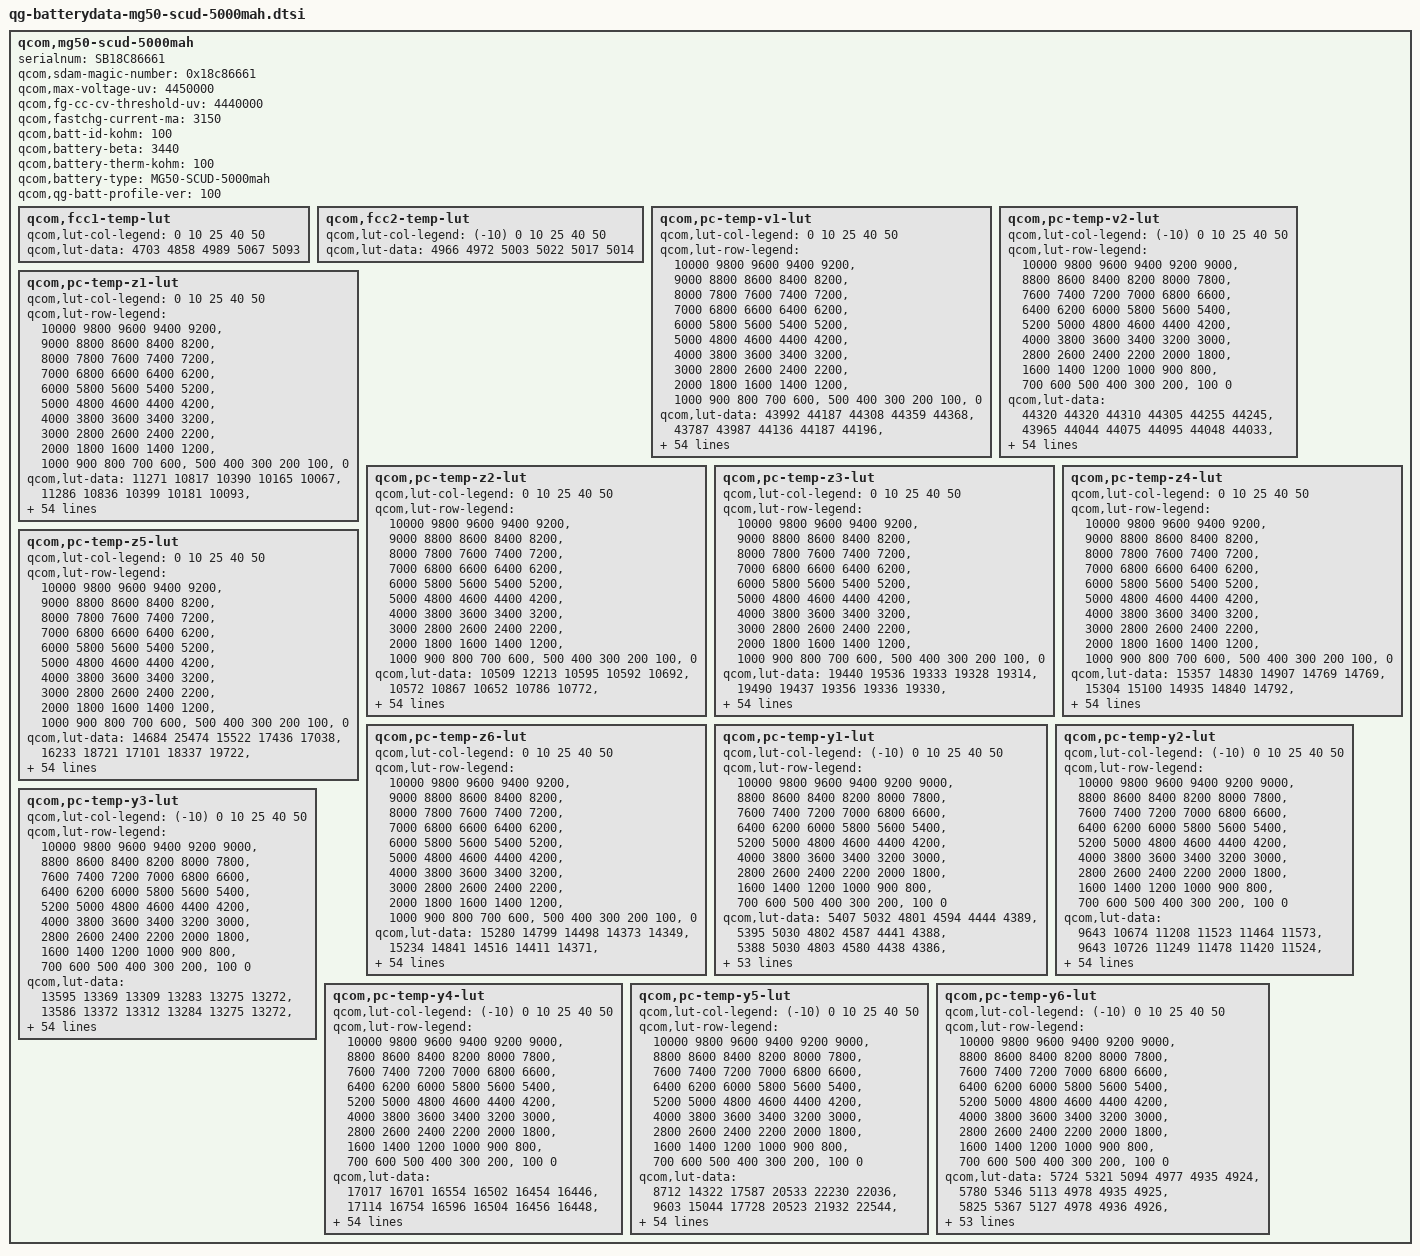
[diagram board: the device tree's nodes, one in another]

qcom,mg50-scud-5000mah {
    /* 4694403_Lenovo_ MG50_5000mAH_PM7150_averaged_MasterSlave_Jul8th2020 */
    serialnum = "SB18C86661";
    qcom,sdam-magic-number = <0x18c86661>;
    qcom,max-voltage-uv = <4450000>;
    qcom,fg-cc-cv-threshold-uv = <4440000>;
    qcom,fastchg-current-ma = <3150>;
    qcom,batt-id-kohm = <100>;
    qcom,battery-beta = <3440>;
    qcom,battery-therm-kohm = <100>;
    qcom,battery-type = "MG50-SCUD-5000mah";
    qcom,qg-batt-profile-ver = <100>;

	qcom,fcc1-temp-lut {
		qcom,lut-col-legend = <0 10 25 40 50>;
		qcom,lut-data = <4703 4858 4989 5067 5093>;
	};

	qcom,fcc2-temp-lut {
		qcom,lut-col-legend = <(-10) 0 10 25 40 50>;
		qcom,lut-data = <4966 4972 5003 5022 5017 5014>;
	};

	qcom,pc-temp-v1-lut {
		qcom,lut-col-legend = <0 10 25 40 50>;
		qcom,lut-row-legend = <10000 9800 9600 9400 9200>,
			<9000 8800 8600 8400 8200>,
			<8000 7800 7600 7400 7200>,
			<7000 6800 6600 6400 6200>,
			<6000 5800 5600 5400 5200>,
			<5000 4800 4600 4400 4200>,
			<4000 3800 3600 3400 3200>,
			<3000 2800 2600 2400 2200>,
			<2000 1800 1600 1400 1200>,
			<1000 900 800 700 600>,
			<500 400 300 200 100>,
			<0>;
		qcom,lut-data = <43992 44187 44308 44359 44368>,
			<43787 43987 44136 44187 44196>,
			<43576 43790 43955 44013 44021>,
			<43356 43593 43768 43830 43841>,
			<43130 43382 43574 43639 43649>,
			<42900 43153 43366 43436 43446>,
			<42669 42917 43138 43219 43231>,
			<42437 42681 42897 42986 43003>,
			<42210 42445 42656 42748 42767>,
			<41984 42212 42414 42508 42527>,
			<41763 41981 42176 42267 42284>,
			<41548 41754 41943 42027 42043>,
			<41338 41531 41714 41789 41805>,
			<41135 41313 41487 41554 41570>,
			<40938 41101 41264 41326 41342>,
			<40745 40900 41047 41103 41118>,
			<40544 40703 40841 40888 40901>,
			<40336 40507 40641 40680 40691>,
			<40137 40318 40447 40479 40489>,
			<39960 40111 40260 40289 40296>,
			<39792 39838 40051 40097 40106>,
			<39601 39527 39772 39858 39879>,
			<39348 39311 39483 39569 39596>,
			<39106 39182 39288 39332 39349>,
			<38966 39077 39151 39169 39179>,
			<38877 38974 39027 39033 39041>,
			<38804 38875 38904 38905 38911>,
			<38736 38780 38788 38786 38789>,
			<38674 38688 38681 38676 38677>,
			<38613 38601 38583 38575 38575>,
			<38555 38525 38493 38482 38480>,
			<38499 38456 38411 38396 38389>,
			<38448 38394 38336 38317 38303>,
			<38400 38339 38269 38241 38219>,
			<38353 38289 38211 38167 38140>,
			<38308 38239 38154 38093 38059>,
			<38262 38190 38096 38019 37967>,
			<38200 38131 38036 37942 37864>,
			<38105 38044 37954 37852 37757>,
			<37989 37928 37843 37739 37647>,
			<37860 37799 37718 37611 37526>,
			<37710 37652 37581 37466 37379>,
			<37548 37495 37433 37313 37218>,
			<37386 37322 37270 37162 37076>,
			<37296 37203 37151 37062 36985>,
			<37234 37143 37085 37008 36940>,
			<37213 37119 37064 36991 36919>,
			<37177 37097 37042 36968 36891>,
			<37093 37013 36995 36881 36770>,
			<36837 36728 36765 36589 36457>,
			<36416 36308 36380 36181 36041>,
			<35905 35782 35892 35672 35518>,
			<35256 35108 35271 35016 34844>,
			<34366 34175 34438 34118 33914>,
			<32964 32671 33161 32689 32396>,
			<30000 30000 30000 30000 30000>;
	};

	qcom,pc-temp-v2-lut {
		qcom,lut-col-legend = <(-10) 0 10 25 40 50>;
		qcom,lut-row-legend = <10000 9800 9600 9400 9200 9000>,
			<8800 8600 8400 8200 8000 7800>,
			<7600 7400 7200 7000 6800 6600>,
			<6400 6200 6000 5800 5600 5400>,
			<5200 5000 4800 4600 4400 4200>,
			<4000 3800 3600 3400 3200 3000>,
			<2800 2600 2400 2200 2000 1800>,
			<1600 1400 1200 1000 900 800>,
			<700 600 500 400 300 200>,
			<100 0>;
		qcom,lut-data = <44320 44320 44310 44305 44255 44245>,
			<43965 44044 44075 44095 44048 44033>,
			<43646 43783 43847 43888 43841 43823>,
			<43373 43539 43629 43685 43637 43617>,
			<43143 43315 43421 43488 43435 43416>,
			<42908 43087 43207 43282 43225 43208>,
			<42630 42844 42973 43057 42999 42983>,
			<42340 42594 42730 42821 42764 42748>,
			<42086 42343 42487 42584 42527 42512>,
			<41863 42089 42241 42342 42285 42270>,
			<41647 41842 41999 42102 42045 42029>,
			<41428 41608 41761 41864 41808 41793>,
			<41213 41383 41529 41629 41574 41560>,
			<41004 41167 41299 41397 41343 41330>,
			<40805 40963 41074 41169 41116 41105>,
			<40578 40755 40857 40947 40896 40885>,
			<40259 40529 40659 40736 40686 40673>,
			<39887 40290 40462 40529 40481 40466>,
			<39600 40041 40233 40320 40280 40266>,
			<39384 39773 39964 40108 40081 40074>,
			<39175 39515 39701 39882 39866 39865>,
			<38919 39278 39458 39614 39598 39600>,
			<38655 39058 39235 39349 39329 39331>,
			<38476 38866 39047 39147 39129 39131>,
			<38357 38700 38886 38984 38972 38974>,
			<38268 38544 38739 38838 38832 38835>,
			<38200 38376 38602 38707 38702 38704>,
			<38145 38214 38476 38587 38583 38585>,
			<38091 38108 38361 38475 38473 38473>,
			<38039 38040 38255 38370 38369 38369>,
			<37988 37985 38157 38273 38275 38273>,
			<37936 37937 38060 38184 38191 38188>,
			<37883 37894 37970 38101 38111 38107>,
			<37825 37849 37897 38020 38020 38010>,
			<37765 37801 37839 37941 37922 37899>,
			<37700 37750 37782 37854 37818 37781>,
			<37631 37693 37725 37753 37704 37659>,
			<37555 37629 37664 37647 37588 37540>,
			<37471 37549 37587 37551 37483 37435>,
			<37374 37443 37489 37460 37385 37340>,
			<37268 37320 37378 37358 37278 37235>,
			<37155 37185 37245 37239 37152 37105>,
			<37039 37047 37105 37110 37022 36966>,
			<36935 36937 36976 36976 36901 36845>,
			<36842 36840 36886 36904 36847 36794>,
			<36755 36736 36814 36872 36826 36773>,
			<36697 36666 36774 36851 36804 36749>,
			<36625 36570 36701 36819 36747 36685>,
			<36516 36434 36561 36717 36519 36442>,
			<36310 36227 36288 36408 36124 36042>,
			<35943 35905 35849 35958 35619 35539>,
			<35435 35440 35261 35395 34979 34899>,
			<34753 34787 34498 34661 34122 34049>,
			<33802 33857 33411 33658 32882 32885>,
			<32232 32353 31745 32182 31983 31219>,
			<29119 29764 27700 30619 28847 27763>;
	};

	qcom,pc-temp-z1-lut {
		qcom,lut-col-legend = <0 10 25 40 50>;
		qcom,lut-row-legend = <10000 9800 9600 9400 9200>,
			<9000 8800 8600 8400 8200>,
			<8000 7800 7600 7400 7200>,
			<7000 6800 6600 6400 6200>,
			<6000 5800 5600 5400 5200>,
			<5000 4800 4600 4400 4200>,
			<4000 3800 3600 3400 3200>,
			<3000 2800 2600 2400 2200>,
			<2000 1800 1600 1400 1200>,
			<1000 900 800 700 600>,
			<500 400 300 200 100>,
			<0>;
		qcom,lut-data = <11271 10817 10390 10165 10067>,
			<11286 10836 10399 10181 10093>,
			<11296 10836 10405 10182 10097>,
			<11300 10829 10405 10181 10098>,
			<11299 10822 10395 10176 10098>,
			<11292 10819 10383 10169 10096>,
			<11279 10816 10368 10164 10094>,
			<11261 10801 10354 10160 10093>,
			<11237 10778 10347 10157 10092>,
			<11206 10765 10343 10154 10091>,
			<11187 10758 10340 10151 10090>,
			<11181 10753 10336 10149 10088>,
			<11176 10747 10333 10147 10087>,
			<11171 10741 10331 10146 10087>,
			<11161 10738 10330 10145 10087>,
			<11153 10737 10328 10144 10087>,
			<11151 10737 10326 10144 10087>,
			<11142 10737 10325 10143 10088>,
			<11134 10738 10325 10144 10088>,
			<11136 10739 10327 10144 10089>,
			<11142 10738 10327 10145 10090>,
			<11147 10738 10328 10146 10090>,
			<11145 10741 10328 10146 10091>,
			<11144 10748 10329 10147 10092>,
			<11146 10754 10331 10149 10094>,
			<11153 10756 10333 10152 10096>,
			<11159 10757 10337 10154 10098>,
			<11160 10757 10343 10157 10100>,
			<11158 10757 10346 10160 10102>,
			<11160 10758 10349 10164 10105>,
			<11172 10759 10353 10167 10107>,
			<11182 10760 10360 10170 10110>,
			<11181 10761 10368 10174 10113>,
			<11179 10762 10373 10178 10116>,
			<11178 10765 10377 10183 10120>,
			<11180 10769 10380 10187 10123>,
			<11183 10777 10384 10192 10126>,
			<11188 10786 10388 10195 10130>,
			<11200 10795 10393 10200 10133>,
			<11213 10805 10399 10205 10136>,
			<11221 10810 10405 10209 10139>,
			<11232 10809 10410 10213 10142>,
			<11239 10812 10417 10216 10144>,
			<11244 10828 10424 10218 10146>,
			<11262 10834 10432 10223 10148>,
			<11246 10832 10440 10227 10151>,
			<11236 10824 10440 10229 10153>,
			<11251 10838 10438 10231 10155>,
			<11270 10838 10445 10237 10158>,
			<11265 10850 10448 10240 10161>,
			<11282 10857 10455 10247 10167>,
			<11289 10871 10468 10252 10172>,
			<11290 10887 10487 10262 10181>,
			<11311 10903 10491 10275 10192>,
			<11311 10903 10491 10275 10192>,
			<11311 10903 10491 10275 10192>;
	};

	qcom,pc-temp-z2-lut {
		qcom,lut-col-legend = <0 10 25 40 50>;
		qcom,lut-row-legend = <10000 9800 9600 9400 9200>,
			<9000 8800 8600 8400 8200>,
			<8000 7800 7600 7400 7200>,
			<7000 6800 6600 6400 6200>,
			<6000 5800 5600 5400 5200>,
			<5000 4800 4600 4400 4200>,
			<4000 3800 3600 3400 3200>,
			<3000 2800 2600 2400 2200>,
			<2000 1800 1600 1400 1200>,
			<1000 900 800 700 600>,
			<500 400 300 200 100>,
			<0>;
		qcom,lut-data = <10509 12213 10595 10592 10692>,
			<10572 10867 10652 10786 10772>,
			<10596 10761 10823 10834 10920>,
			<10589 10757 11229 10840 10927>,
			<10565 10738 12090 10771 10875>,
			<10534 10690 12548 10673 10800>,
			<10494 10640 11850 10625 10750>,
			<10455 10591 10829 10597 10695>,
			<10428 10542 10590 10570 10635>,
			<10405 10522 10589 10528 10615>,
			<10389 10529 10622 10490 10609>,
			<10382 10544 10996 10484 10600>,
			<10377 10554 11370 10500 10572>,
			<10378 10561 11441 10514 10545>,
			<10390 10570 11479 10512 10547>,
			<10408 10582 11533 10508 10566>,
			<10421 10596 11872 10521 10593>,
			<10432 10609 12572 10557 10635>,
			<10441 10619 12909 10590 10674>,
			<10450 10634 13044 10609 10697>,
			<10459 10668 13073 10628 10719>,
			<10469 10712 12280 10682 10783>,
			<10485 10719 11069 10800 10972>,
			<10497 10658 10768 10928 11106>,
			<10499 10601 10760 11085 11091>,
			<10498 10605 10778 11196 11017>,
			<10497 10636 10834 11108 10917>,
			<10495 10663 10888 10829 10735>,
			<10492 10682 10862 10655 10601>,
			<10492 10694 10767 10587 10517>,
			<10497 10693 10696 10542 10464>,
			<10507 10683 10681 10513 10470>,
			<10514 10676 10685 10491 10518>,
			<10520 10681 10700 10491 10578>,
			<10526 10690 10722 10552 10648>,
			<10534 10700 10750 10640 10729>,
			<10543 10713 10792 10709 10829>,
			<10552 10728 10845 10779 10951>,
			<10561 10742 10901 10864 11008>,
			<10568 10758 10969 10991 11017>,
			<10567 10761 11003 11074 11022>,
			<10563 10744 10961 11069 11032>,
			<10565 10733 10913 11047 11034>,
			<10576 10738 10910 11004 11005>,
			<10421 10832 10883 10888 10900>,
			<10358 10830 10793 10764 10801>,
			<10255 10808 10772 10793 10842>,
			<10301 10812 10794 10878 10982>,
			<10399 10874 10866 10897 10969>,
			<10414 10909 10847 10684 10662>,
			<10102 10754 10705 10587 10591>,
			<10025 10700 10660 10537 10539>,
			<9921 10549 10590 10477 10489>,
			<9728 10435 10529 10406 10393>,
			<9728 10435 10529 10406 10393>,
			<9728 10435 10529 10406 10393>;
	};

	qcom,pc-temp-z3-lut {
		qcom,lut-col-legend = <0 10 25 40 50>;
		qcom,lut-row-legend = <10000 9800 9600 9400 9200>,
			<9000 8800 8600 8400 8200>,
			<8000 7800 7600 7400 7200>,
			<7000 6800 6600 6400 6200>,
			<6000 5800 5600 5400 5200>,
			<5000 4800 4600 4400 4200>,
			<4000 3800 3600 3400 3200>,
			<3000 2800 2600 2400 2200>,
			<2000 1800 1600 1400 1200>,
			<1000 900 800 700 600>,
			<500 400 300 200 100>,
			<0>;
		qcom,lut-data = <19440 19536 19333 19328 19314>,
			<19490 19437 19356 19336 19330>,
			<19522 19430 19374 19350 19343>,
			<19539 19445 19391 19360 19351>,
			<19550 19455 19409 19364 19357>,
			<19556 19463 19417 19368 19362>,
			<19559 19468 19413 19369 19363>,
			<19560 19469 19404 19369 19362>,
			<19560 19468 19397 19369 19360>,
			<19559 19465 19393 19366 19358>,
			<19557 19459 19392 19363 19356>,
			<19553 19453 19395 19361 19355>,
			<19548 19449 19397 19359 19353>,
			<19541 19446 19395 19358 19351>,
			<19533 19443 19391 19355 19348>,
			<19527 19440 19388 19353 19345>,
			<19525 19438 19388 19350 19342>,
			<19525 19435 19389 19348 19339>,
			<19524 19432 19388 19345 19336>,
			<19523 19430 19385 19341 19332>,
			<19522 19436 19381 19337 19329>,
			<19523 19449 19378 19337 19329>,
			<19531 19453 19374 19340 19332>,
			<19540 19441 19370 19345 19338>,
			<19540 19429 19364 19363 19354>,
			<19535 19429 19363 19383 19374>,
			<19530 19431 19376 19385 19377>,
			<19526 19435 19393 19382 19372>,
			<19524 19442 19397 19378 19367>,
			<19522 19448 19397 19372 19359>,
			<19522 19449 19394 19365 19352>,
			<19521 19448 19390 19359 19346>,
			<19521 19446 19385 19352 19341>,
			<19520 19444 19380 19346 19336>,
			<19519 19442 19375 19340 19329>,
			<19517 19439 19371 19337 19323>,
			<19514 19436 19368 19337 19324>,
			<19510 19433 19366 19337 19329>,
			<19506 19429 19366 19338 19332>,
			<19501 19426 19367 19342 19333>,
			<19498 19423 19368 19345 19334>,
			<19496 19421 19366 19345 19336>,
			<19491 19418 19363 19346 19337>,
			<19481 19415 19363 19348 19338>,
			<19357 19398 19354 19341 19335>,
			<19306 19386 19341 19324 19315>,
			<19263 19385 19338 19318 19311>,
			<19262 19377 19336 19313 19305>,
			<19262 19374 19328 19315 19309>,
			<19262 19372 19340 19332 19322>,
			<19264 19363 19348 19334 19323>,
			<19264 19361 19350 19335 19323>,
			<19265 19353 19351 19336 19324>,
			<19269 19347 19351 19335 19326>,
			<19269 19347 19351 19335 19326>,
			<19269 19347 19351 19335 19326>;
	};

	qcom,pc-temp-z4-lut {
		qcom,lut-col-legend = <0 10 25 40 50>;
		qcom,lut-row-legend = <10000 9800 9600 9400 9200>,
			<9000 8800 8600 8400 8200>,
			<8000 7800 7600 7400 7200>,
			<7000 6800 6600 6400 6200>,
			<6000 5800 5600 5400 5200>,
			<5000 4800 4600 4400 4200>,
			<4000 3800 3600 3400 3200>,
			<3000 2800 2600 2400 2200>,
			<2000 1800 1600 1400 1200>,
			<1000 900 800 700 600>,
			<500 400 300 200 100>,
			<0>;
		qcom,lut-data = <15357 14830 14907 14769 14769>,
			<15304 15100 14935 14840 14792>,
			<15240 15093 14900 14817 14789>,
			<15158 15006 14850 14784 14760>,
			<15063 14931 14782 14758 14737>,
			<14986 14877 14741 14735 14717>,
			<14925 14832 14732 14715 14701>,
			<14875 14796 14727 14698 14689>,
			<14835 14766 14719 14687 14681>,
			<14802 14744 14708 14683 14678>,
			<14775 14726 14695 14681 14676>,
			<14754 14714 14679 14678 14674>,
			<14736 14708 14667 14674 14672>,
			<14724 14705 14663 14670 14670>,
			<14717 14703 14661 14667 14668>,
			<14713 14700 14659 14665 14666>,
			<14714 14698 14651 14662 14664>,
			<14721 14698 14639 14659 14661>,
			<14727 14701 14636 14658 14658>,
			<14727 14706 14638 14658 14657>,
			<14726 14734 14644 14659 14656>,
			<14728 14788 14693 14674 14664>,
			<14766 14811 14763 14726 14709>,
			<14812 14812 14781 14753 14740>,
			<14819 14808 14780 14730 14721>,
			<14811 14800 14773 14696 14686>,
			<14801 14783 14750 14685 14674>,
			<14791 14767 14721 14680 14671>,
			<14781 14753 14708 14677 14668>,
			<14771 14741 14700 14675 14666>,
			<14762 14735 14697 14673 14664>,
			<14755 14731 14696 14671 14661>,
			<14749 14730 14696 14669 14657>,
			<14745 14729 14696 14668 14655>,
			<14741 14728 14697 14668 14655>,
			<14736 14727 14698 14669 14655>,
			<14732 14726 14698 14670 14658>,
			<14729 14724 14698 14672 14665>,
			<14728 14723 14699 14674 14668>,
			<14726 14722 14700 14676 14669>,
			<14723 14719 14700 14678 14669>,
			<14715 14711 14697 14679 14673>,
			<14706 14701 14689 14679 14680>,
			<14694 14690 14681 14673 14673>,
			<14748 14660 14661 14655 14651>,
			<14788 14642 14643 14637 14631>,
			<14828 14637 14635 14628 14621>,
			<14823 14634 14627 14619 14613>,
			<14816 14634 14626 14619 14622>,
			<14819 14646 14635 14634 14640>,
			<14826 14658 14635 14637 14645>,
			<14830 14662 14634 14641 14650>,
			<14834 14674 14637 14645 14654>,
			<14841 14683 14638 14648 14656>,
			<14841 14683 14638 14648 14656>,
			<14841 14683 14638 14648 14656>;
	};

	qcom,pc-temp-z5-lut {
		qcom,lut-col-legend = <0 10 25 40 50>;
		qcom,lut-row-legend = <10000 9800 9600 9400 9200>,
			<9000 8800 8600 8400 8200>,
			<8000 7800 7600 7400 7200>,
			<7000 6800 6600 6400 6200>,
			<6000 5800 5600 5400 5200>,
			<5000 4800 4600 4400 4200>,
			<4000 3800 3600 3400 3200>,
			<3000 2800 2600 2400 2200>,
			<2000 1800 1600 1400 1200>,
			<1000 900 800 700 600>,
			<500 400 300 200 100>,
			<0>;
		qcom,lut-data = <14684 25474 15522 17436 17038>,
			<16233 18721 17101 18337 19722>,
			<17540 18035 18593 19971 21739>,
			<18570 19227 20283 21585 23734>,
			<19478 20478 22468 22506 25650>,
			<20505 21903 23885 23281 27754>,
			<21698 23556 24043 24690 29810>,
			<23003 25124 24099 27004 31547>,
			<24511 26562 24410 28361 32944>,
			<26305 27923 25537 28508 34011>,
			<28109 29379 27154 28482 34958>,
			<29819 30790 30658 29016 35976>,
			<31565 31894 33903 30251 37139>,
			<32996 32796 34892 31511 38030>,
			<33915 33643 35768 32518 38631>,
			<34793 34553 36783 33478 39265>,
			<36269 35331 39435 34706 39914>,
			<38294 35588 43718 36321 41281>,
			<39510 35266 44686 37071 42057>,
			<39741 34971 43173 35971 41923>,
			<39950 40201 41024 34075 41291>,
			<41575 50124 37696 32112 39310>,
			<49877 52387 33016 28758 32555>,
			<58417 41817 28337 26765 28017>,
			<58281 30849 23265 28339 30581>,
			<51712 28946 21140 31323 35413>,
			<45605 28827 23376 33034 37499>,
			<42988 29542 27788 34260 38501>,
			<41237 32826 30871 34744 38858>,
			<40836 37505 33293 34647 37380>,
			<41724 40884 35286 34528 35471>,
			<43275 43701 37360 34523 35635>,
			<45038 45958 39255 34193 37088>,
			<47294 47922 40011 34042 37705>,
			<49172 49390 40371 34661 36111>,
			<50595 49583 40498 35693 34424>,
			<51835 49118 40169 37027 36616>,
			<52209 48420 39534 38714 43285>,
			<51887 47198 39052 39378 45837>,
			<51339 45238 38671 39482 44116>,
			<50744 43580 38206 39596 42378>,
			<49972 42030 37271 40429 42939>,
			<49045 41458 36639 41786 44355>,
			<47555 42006 36646 42995 45986>,
			<29118 46645 36014 38926 43912>,
			<19640 43709 33694 30754 28435>,
			<11807 44486 34917 30977 32659>,
			<11787 38465 39562 36040 40386>,
			<11828 37324 32499 39027 45342>,
			<11905 30216 34474 39082 35144>,
			<11883 23526 34131 34586 29932>,
			<11787 22499 34047 30515 25848>,
			<11616 18590 31060 26767 22678>,
			<11503 17027 27070 21857 19270>,
			<11503 17027 27070 21857 19270>,
			<11503 17027 27070 21857 19270>;
	};

	qcom,pc-temp-z6-lut {
		qcom,lut-col-legend = <0 10 25 40 50>;
		qcom,lut-row-legend = <10000 9800 9600 9400 9200>,
			<9000 8800 8600 8400 8200>,
			<8000 7800 7600 7400 7200>,
			<7000 6800 6600 6400 6200>,
			<6000 5800 5600 5400 5200>,
			<5000 4800 4600 4400 4200>,
			<4000 3800 3600 3400 3200>,
			<3000 2800 2600 2400 2200>,
			<2000 1800 1600 1400 1200>,
			<1000 900 800 700 600>,
			<500 400 300 200 100>,
			<0>;
		qcom,lut-data = <15280 14799 14498 14373 14349>,
			<15234 14841 14516 14411 14371>,
			<15181 14822 14510 14408 14375>,
			<15117 14771 14498 14400 14370>,
			<15046 14724 14476 14391 14364>,
			<14986 14688 14458 14382 14358>,
			<14935 14657 14445 14374 14353>,
			<14892 14630 14435 14366 14347>,
			<14855 14605 14425 14360 14342>,
			<14823 14585 14417 14356 14339>,
			<14797 14569 14410 14353 14337>,
			<14773 14556 14404 14350 14335>,
			<14753 14550 14400 14347 14333>,
			<14738 14546 14396 14344 14330>,
			<14727 14543 14393 14341 14328>,
			<14720 14539 14390 14339 14325>,
			<14719 14535 14387 14336 14323>,
			<14720 14534 14383 14333 14320>,
			<14722 14534 14382 14331 14317>,
			<14721 14533 14381 14329 14314>,
			<14721 14548 14382 14327 14313>,
			<14723 14579 14400 14334 14316>,
			<14745 14590 14426 14359 14338>,
			<14770 14586 14431 14372 14354>,
			<14774 14580 14429 14371 14353>,
			<14770 14575 14426 14370 14351>,
			<14764 14571 14424 14367 14348>,
			<14760 14568 14422 14364 14345>,
			<14755 14567 14419 14361 14341>,
			<14751 14566 14417 14357 14337>,
			<14749 14566 14414 14353 14333>,
			<14747 14565 14413 14349 14328>,
			<14747 14565 14411 14345 14324>,
			<14747 14565 14410 14342 14321>,
			<14748 14565 14409 14340 14317>,
			<14748 14565 14408 14339 14315>,
			<14749 14565 14408 14339 14316>,
			<14749 14566 14408 14341 14322>,
			<14752 14567 14409 14343 14325>,
			<14756 14569 14412 14346 14326>,
			<14759 14569 14414 14349 14328>,
			<14762 14569 14413 14351 14331>,
			<14764 14568 14410 14352 14335>,
			<14765 14568 14408 14350 14333>,
			<14745 14557 14397 14340 14322>,
			<14737 14547 14385 14324 14303>,
			<14735 14545 14381 14318 14297>,
			<14735 14542 14376 14311 14290>,
			<14738 14545 14374 14313 14297>,
			<14745 14553 14386 14330 14313>,
			<14754 14558 14392 14334 14317>,
			<14762 14564 14395 14337 14321>,
			<14774 14572 14401 14342 14326>,
			<14792 14583 14406 14346 14331>,
			<14792 14583 14406 14346 14331>,
			<14792 14583 14406 14346 14331>;
	};

	qcom,pc-temp-y1-lut {
		qcom,lut-col-legend = <(-10) 0 10 25 40 50>;
		qcom,lut-row-legend = <10000 9800 9600 9400 9200 9000>,
			<8800 8600 8400 8200 8000 7800>,
			<7600 7400 7200 7000 6800 6600>,
			<6400 6200 6000 5800 5600 5400>,
			<5200 5000 4800 4600 4400 4200>,
			<4000 3800 3600 3400 3200 3000>,
			<2800 2600 2400 2200 2000 1800>,
			<1600 1400 1200 1000 900 800>,
			<700 600 500 400 300 200>,
			<100 0>;
		qcom,lut-data = <5407 5032 4801 4594 4444 4389>,
			<5395 5030 4802 4587 4441 4388>,
			<5388 5030 4803 4580 4438 4386>,
			<5383 5032 4804 4573 4435 4385>,
			<5381 5035 4804 4566 4432 4383>,
			<5381 5036 4804 4561 4429 4382>,
			<5386 5036 4802 4558 4426 4380>,
			<5394 5038 4800 4554 4423 4378>,
			<5395 5037 4799 4550 4421 4377>,
			<5392 5030 4798 4544 4418 4376>,
			<5390 5025 4799 4539 4415 4376>,
			<5397 5028 4797 4536 4413 4374>,
			<5409 5034 4794 4534 4411 4373>,
			<5412 5038 4793 4532 4410 4373>,
			<5409 5040 4793 4530 4409 4373>,
			<5407 5043 4793 4529 4409 4373>,
			<5409 5046 4795 4527 4409 4373>,
			<5411 5051 4796 4526 4409 4373>,
			<5412 5053 4795 4526 4409 4373>,
			<5410 5053 4791 4526 4408 4373>,
			<5408 5053 4790 4527 4408 4373>,
			<5409 5056 4793 4527 4409 4374>,
			<5409 5059 4797 4528 4410 4375>,
			<5408 5060 4798 4529 4411 4375>,
			<5402 5060 4799 4532 4412 4376>,
			<5397 5061 4801 4534 4413 4377>,
			<5399 5061 4803 4536 4414 4378>,
			<5402 5062 4807 4539 4416 4379>,
			<5405 5061 4810 4541 4418 4380>,
			<5413 5060 4812 4544 4420 4381>,
			<5418 5059 4813 4547 4422 4383>,
			<5411 5062 4812 4550 4424 4384>,
			<5397 5066 4811 4554 4426 4385>,
			<5393 5066 4813 4558 4428 4387>,
			<5396 5065 4817 4562 4429 4388>,
			<5400 5064 4819 4565 4431 4390>,
			<5399 5068 4819 4567 4434 4392>,
			<5394 5075 4821 4570 4436 4393>,
			<5393 5077 4825 4572 4439 4395>,
			<5401 5072 4832 4574 4441 4396>,
			<5408 5067 4836 4576 4443 4398>,
			<5410 5064 4830 4579 4445 4400>,
			<5412 5065 4830 4581 4447 4402>,
			<5430 5066 4838 4585 4450 4403>,
			<5427 5077 4835 4595 4453 4405>,
			<5435 5091 4843 4593 4455 4406>,
			<5426 5093 4835 4597 4454 4406>,
			<5451 5086 4846 4597 4454 4408>,
			<5435 5090 4844 4594 4454 4408>,
			<5437 5095 4839 4594 4457 4410>,
			<5463 5109 4852 4606 4462 4414>,
			<5479 5117 4860 4607 4467 4418>,
			<5491 5131 4865 4617 4474 4424>,
			<5544 5167 4885 4635 4486 4435>,
			<5544 5167 4885 4635 4486 4435>,
			<5544 5167 4885 4635 4486 4435>;
	};

	qcom,pc-temp-y2-lut {
		qcom,lut-col-legend = <(-10) 0 10 25 40 50>;
		qcom,lut-row-legend = <10000 9800 9600 9400 9200 9000>,
			<8800 8600 8400 8200 8000 7800>,
			<7600 7400 7200 7000 6800 6600>,
			<6400 6200 6000 5800 5600 5400>,
			<5200 5000 4800 4600 4400 4200>,
			<4000 3800 3600 3400 3200 3000>,
			<2800 2600 2400 2200 2000 1800>,
			<1600 1400 1200 1000 900 800>,
			<700 600 500 400 300 200>,
			<100 0>;
		qcom,lut-data = <9643 10674 11208 11523 11464 11573>,
			<9643 10726 11249 11478 11420 11524>,
			<9643 10832 11276 11433 11361 11465>,
			<9958 10956 11290 11390 11298 11404>,
			<10373 11058 11296 11347 11242 11349>,
			<10553 11102 11297 11307 11204 11308>,
			<10545 11100 11283 11264 11179 11277>,
			<10530 11096 11257 11226 11156 11247>,
			<10568 11096 11238 11209 11135 11209>,
			<10830 11110 11222 11196 11113 11156>,
			<11020 11129 11214 11190 11100 11129>,
			<10775 11163 11228 11190 11101 11136>,
			<10354 11208 11259 11190 11104 11148>,
			<10240 11239 11290 11193 11102 11149>,
			<10350 11260 11328 11202 11102 11134>,
			<10387 11290 11379 11217 11112 11128>,
			<10131 11414 11494 11274 11151 11131>,
			<9761 11588 11617 11368 11217 11138>,
			<9685 11612 11631 11474 11312 11178>,
			<9682 11490 11590 11613 11460 11310>,
			<9679 11360 11545 11674 11531 11421>,
			<9676 11292 11507 11584 11498 11469>,
			<9674 11238 11473 11468 11447 11500>,
			<9672 11193 11460 11453 11433 11507>,
			<9671 11159 11453 11469 11431 11512>,
			<9669 11109 11451 11488 11436 11518>,
			<9668 10816 11452 11522 11487 11542>,
			<9667 10318 11452 11567 11545 11571>,
			<9666 10076 11448 11601 11567 11593>,
			<9665 9961 11437 11634 11591 11617>,
			<9664 9876 11421 11669 11619 11650>,
			<9663 9811 11373 11722 11688 11727>,
			<9663 9761 11326 11763 11751 11832>,
			<9663 9730 11334 11764 11758 11855>,
			<9662 9711 11386 11750 11746 11807>,
			<9662 9698 11419 11732 11740 11764>,
			<9662 9689 11398 11701 11724 11764>,
			<9661 9682 11346 11661 11696 11766>,
			<9661 9677 11275 11637 11655 11739>,
			<9661 9673 11174 11618 11593 11683>,
			<9661 9669 11065 11593 11542 11646>,
			<9661 9667 10964 11554 11517 11627>,
			<9660 9665 10791 11546 11509 11619>,
			<9660 9663 10340 11510 11502 11561>,
			<9660 9662 10038 11439 11389 11387>,
			<9659 9661 10120 11395 11399 11346>,
			<9659 9661 10280 11435 11417 11352>,
			<9659 9661 10284 11505 11469 11331>,
			<9658 9661 10294 11538 11333 11289>,
			<9658 9660 10278 11418 11281 11277>,
			<9657 9660 10110 11321 11203 11192>,
			<9657 9659 9799 11263 11084 11086>,
			<9656 9658 9719 11192 10987 10900>,
			<9653 9657 9697 11161 10730 10618>,
			<9653 9657 9697 11161 10730 10618>,
			<9653 9657 9697 11161 10730 10618>;
	};

	qcom,pc-temp-y3-lut {
		qcom,lut-col-legend = <(-10) 0 10 25 40 50>;
		qcom,lut-row-legend = <10000 9800 9600 9400 9200 9000>,
			<8800 8600 8400 8200 8000 7800>,
			<7600 7400 7200 7000 6800 6600>,
			<6400 6200 6000 5800 5600 5400>,
			<5200 5000 4800 4600 4400 4200>,
			<4000 3800 3600 3400 3200 3000>,
			<2800 2600 2400 2200 2000 1800>,
			<1600 1400 1200 1000 900 800>,
			<700 600 500 400 300 200>,
			<100 0>;
		qcom,lut-data = <13595 13369 13309 13283 13275 13272>,
			<13586 13372 13312 13284 13275 13272>,
			<13576 13377 13316 13285 13276 13273>,
			<13566 13382 13319 13286 13276 13274>,
			<13556 13386 13322 13287 13277 13275>,
			<13548 13388 13323 13288 13278 13275>,
			<13539 13389 13325 13289 13278 13276>,
			<13531 13389 13325 13289 13279 13276>,
			<13532 13390 13326 13289 13279 13277>,
			<13543 13390 13326 13290 13280 13277>,
			<13551 13391 13327 13290 13280 13277>,
			<13525 13398 13327 13291 13281 13277>,
			<13474 13409 13328 13291 13281 13278>,
			<13455 13406 13328 13291 13282 13279>,
			<13464 13373 13327 13291 13282 13280>,
			<13476 13348 13325 13291 13282 13280>,
			<13476 13353 13322 13293 13283 13280>,
			<13473 13362 13319 13295 13285 13280>,
			<13470 13363 13316 13295 13286 13280>,
			<13471 13352 13313 13294 13286 13281>,
			<13471 13340 13310 13293 13286 13282>,
			<13468 13334 13306 13289 13282 13280>,
			<13462 13329 13303 13284 13277 13276>,
			<13461 13324 13301 13282 13276 13274>,
			<13472 13322 13300 13281 13275 13274>,
			<13489 13318 13299 13281 13275 13274>,
			<13515 13305 13298 13281 13275 13274>,
			<13552 13287 13297 13281 13275 13274>,
			<13590 13285 13296 13281 13275 13274>,
			<13630 13300 13294 13280 13274 13273>,
			<13673 13313 13294 13280 13274 13273>,
			<13720 13319 13293 13280 13274 13273>,
			<13772 13325 13292 13280 13275 13273>,
			<13826 13333 13293 13280 13275 13274>,
			<13882 13344 13294 13280 13275 13273>,
			<13940 13358 13295 13279 13275 13273>,
			<14001 13381 13296 13278 13274 13272>,
			<14064 13414 13298 13277 13273 13272>,
			<14122 13454 13299 13277 13273 13272>,
			<14175 13502 13301 13278 13274 13273>,
			<14224 13558 13304 13278 13274 13273>,
			<14269 13621 13307 13278 13275 13273>,
			<14313 13695 13310 13278 13274 13272>,
			<14361 13789 13316 13279 13273 13272>,
			<14420 13895 13328 13281 13275 13274>,
			<14468 13939 13333 13284 13280 13277>,
			<14492 13932 13339 13287 13281 13278>,
			<14536 13965 13347 13290 13281 13277>,
			<14606 13995 13353 13290 13278 13275>,
			<14670 14028 13357 13286 13278 13274>,
			<14765 14075 13365 13287 13279 13276>,
			<14937 14172 13393 13290 13281 13279>,
			<15199 14335 13448 13295 13287 13287>,
			<16083 14568 13556 13306 13296 13295>,
			<16083 14568 13556 13306 13296 13295>,
			<16083 14568 13556 13306 13296 13295>;
	};

	qcom,pc-temp-y4-lut {
		qcom,lut-col-legend = <(-10) 0 10 25 40 50>;
		qcom,lut-row-legend = <10000 9800 9600 9400 9200 9000>,
			<8800 8600 8400 8200 8000 7800>,
			<7600 7400 7200 7000 6800 6600>,
			<6400 6200 6000 5800 5600 5400>,
			<5200 5000 4800 4600 4400 4200>,
			<4000 3800 3600 3400 3200 3000>,
			<2800 2600 2400 2200 2000 1800>,
			<1600 1400 1200 1000 900 800>,
			<700 600 500 400 300 200>,
			<100 0>;
		qcom,lut-data = <17017 16701 16554 16502 16454 16446>,
			<17114 16754 16596 16504 16456 16448>,
			<17210 16836 16643 16505 16458 16451>,
			<17295 16924 16687 16506 16459 16453>,
			<17355 16995 16719 16506 16459 16454>,
			<17379 17025 16732 16506 16459 16455>,
			<17365 17021 16726 16502 16458 16454>,
			<17335 17012 16714 16497 16457 16454>,
			<17308 17001 16704 16495 16457 16453>,
			<17278 16983 16692 16494 16457 16453>,
			<17261 16966 16687 16494 16457 16453>,
			<17350 16952 16687 16495 16458 16453>,
			<17508 16940 16689 16498 16460 16454>,
			<17542 16955 16693 16503 16463 16455>,
			<17493 17071 16708 16511 16468 16457>,
			<17417 17157 16730 16522 16474 16460>,
			<17294 17128 16779 16536 16481 16466>,
			<17132 17057 16834 16555 16490 16474>,
			<17032 16989 16833 16579 16508 16489>,
			<16977 16920 16772 16610 16540 16517>,
			<16921 16855 16705 16622 16556 16531>,
			<16815 16797 16650 16574 16522 16504>,
			<16691 16745 16604 16508 16474 16465>,
			<16646 16704 16582 16488 16462 16455>,
			<16637 16673 16570 16480 16458 16452>,
			<16633 16646 16561 16477 16457 16452>,
			<16634 16615 16555 16478 16457 16452>,
			<16638 16581 16550 16480 16459 16453>,
			<16643 16562 16547 16483 16461 16454>,
			<16651 16553 16545 16489 16466 16457>,
			<16659 16551 16541 16494 16471 16462>,
			<16668 16562 16528 16501 16481 16469>,
			<16676 16584 16512 16507 16489 16478>,
			<16685 16604 16508 16510 16490 16481>,
			<16696 16624 16508 16511 16488 16480>,
			<16707 16641 16509 16511 16485 16477>,
			<16715 16655 16518 16492 16475 16470>,
			<16720 16666 16533 16470 16466 16464>,
			<16722 16670 16546 16465 16465 16467>,
			<16721 16669 16557 16464 16467 16478>,
			<16719 16669 16569 16465 16469 16484>,
			<16715 16669 16579 16469 16469 16482>,
			<16711 16670 16588 16471 16465 16471>,
			<16715 16689 16601 16466 16444 16440>,
			<16736 16746 16631 16472 16446 16442>,
			<16768 16813 16655 16492 16505 16524>,
			<16762 16830 16686 16518 16556 16576>,
			<16792 16899 16747 16564 16584 16588>,
			<16813 16972 16796 16582 16503 16503>,
			<16820 17023 16799 16521 16471 16474>,
			<16808 17034 16780 16510 16474 16476>,
			<16805 17026 16796 16527 16480 16478>,
			<16835 17029 16865 16547 16492 16488>,
			<17134 17090 16970 16609 16627 16638>,
			<17134 17090 16970 16609 16627 16638>,
			<17134 17090 16970 16609 16627 16638>;
	};

	qcom,pc-temp-y5-lut {
		qcom,lut-col-legend = <(-10) 0 10 25 40 50>;
		qcom,lut-row-legend = <10000 9800 9600 9400 9200 9000>,
			<8800 8600 8400 8200 8000 7800>,
			<7600 7400 7200 7000 6800 6600>,
			<6400 6200 6000 5800 5600 5400>,
			<5200 5000 4800 4600 4400 4200>,
			<4000 3800 3600 3400 3200 3000>,
			<2800 2600 2400 2200 2000 1800>,
			<1600 1400 1200 1000 900 800>,
			<700 600 500 400 300 200>,
			<100 0>;
		qcom,lut-data = <8712 14322 17587 20533 22230 22036>,
			<9603 15044 17728 20523 21932 22544>,
			<11696 15744 17888 20377 21564 22916>,
			<14006 16394 18054 20163 21192 23170>,
			<15946 16968 18212 19951 20880 23324>,
			<16924 17439 18349 19806 20692 23396>,
			<17078 17873 18500 19465 20610 23345>,
			<17170 18210 18633 19013 20546 23156>,
			<17619 18267 18630 18806 20392 22756>,
			<19331 18246 18444 18439 20015 21691>,
			<20518 18232 18201 18051 19624 21004>,
			<19187 18692 17903 17711 19308 21004>,
			<16836 19459 17508 17322 18948 20970>,
			<16758 19308 17000 16785 18339 20659>,
			<20076 17267 16270 16006 17318 20122>,
			<22591 15776 15898 15628 16790 19503>,
			<21178 17459 16165 15685 16885 18330>,
			<18445 20576 16826 15836 17112 17041>,
			<17933 21377 17906 16367 17406 16885>,
			<19639 21255 19923 18011 17886 17389>,
			<21008 21160 21266 19447 18478 18150>,
			<19894 21262 21612 20293 19443 19922>,
			<17044 21515 21834 20936 20383 21770>,
			<15057 21827 22116 21228 20763 22304>,
			<13702 22383 22462 21153 21006 22601>,
			<13009 22776 22620 21002 21095 22708>,
			<13082 20196 22410 21131 20823 22385>,
			<13301 15151 22061 21336 20291 21697>,
			<13452 13626 22030 21161 19673 20839>,
			<13531 13973 22258 20501 18843 19647>,
			<13597 14262 22586 20209 18437 18861>,
			<13707 14313 23254 20676 18654 18766>,
			<13902 14371 23941 21448 19142 19041>,
			<14012 14469 24041 22117 19966 19814>,
			<14017 14646 23849 22777 21314 21124>,
			<14015 14929 23597 23381 22258 21942>,
			<14070 15702 23115 24033 22688 22516>,
			<14221 16875 22260 24501 23043 23156>,
			<14301 17265 21364 24335 23594 23899>,
			<14245 17183 20503 23487 24255 24712>,
			<14129 17004 19938 22468 24567 25132>,
			<13857 16281 19604 21210 24619 25132>,
			<13556 15179 19160 20691 24539 25138>,
			<13459 14845 17991 20834 22613 25096>,
			<13455 14687 17081 19929 20124 22669>,
			<13566 15306 17000 19683 20083 18178>,
			<13795 16406 17813 19796 17810 16451>,
			<14116 17143 18078 19715 17137 15811>,
			<15220 17914 18720 19781 18226 17237>,
			<15571 18444 18906 20698 19694 17619>,
			<14676 18232 18106 20741 18696 17036>,
			<14264 17141 16287 20495 18831 17132>,
			<13671 15396 14868 20620 21321 21072>,
			<11967 13181 13690 22663 24601 24431>,
			<11967 13181 13690 22663 24601 24431>,
			<11967 13181 13690 22663 24601 24431>;
	};

	qcom,pc-temp-y6-lut {
		qcom,lut-col-legend = <(-10) 0 10 25 40 50>;
		qcom,lut-row-legend = <10000 9800 9600 9400 9200 9000>,
			<8800 8600 8400 8200 8000 7800>,
			<7600 7400 7200 7000 6800 6600>,
			<6400 6200 6000 5800 5600 5400>,
			<5200 5000 4800 4600 4400 4200>,
			<4000 3800 3600 3400 3200 3000>,
			<2800 2600 2400 2200 2000 1800>,
			<1600 1400 1200 1000 900 800>,
			<700 600 500 400 300 200>,
			<100 0>;
		qcom,lut-data = <5724 5321 5094 4977 4935 4924>,
			<5780 5346 5113 4978 4935 4925>,
			<5825 5367 5127 4978 4936 4926>,
			<5856 5383 5136 4978 4936 4927>,
			<5876 5393 5141 4978 4936 4928>,
			<5882 5397 5142 4977 4936 4928>,
			<5870 5393 5139 4975 4936 4928>,
			<5849 5385 5132 4973 4936 4928>,
			<5842 5376 5126 4971 4936 4929>,
			<5840 5366 5120 4970 4936 4928>,
			<5839 5360 5117 4970 4936 4928>,
			<5838 5359 5115 4970 4937 4929>,
			<5838 5359 5114 4971 4938 4930>,
			<5838 5360 5114 4972 4939 4931>,
			<5836 5369 5116 4974 4940 4932>,
			<5831 5376 5119 4976 4942 4933>,
			<5795 5371 5129 4981 4944 4935>,
			<5732 5359 5142 4988 4948 4937>,
			<5704 5343 5140 4995 4954 4941>,
			<5696 5318 5121 5002 4964 4950>,
			<5688 5294 5100 5005 4968 4954>,
			<5666 5275 5082 4989 4955 4945>,
			<5638 5260 5067 4967 4938 4930>,
			<5632 5252 5060 4960 4933 4926>,
			<5645 5247 5057 4957 4932 4925>,
			<5666 5242 5055 4956 4931 4925>,
			<5692 5233 5054 4957 4932 4925>,
			<5726 5222 5053 4958 4932 4925>,
			<5761 5221 5053 4959 4933 4926>,
			<5796 5234 5054 4961 4934 4927>,
			<5834 5254 5055 4962 4936 4928>,
			<5873 5274 5054 4965 4939 4930>,
			<5916 5300 5052 4968 4942 4933>,
			<5961 5328 5053 4969 4942 4934>,
			<6008 5360 5057 4970 4942 4934>,
			<6056 5396 5063 4970 4941 4933>,
			<6104 5437 5071 4965 4938 4931>,
			<6152 5484 5082 4958 4935 4929>,
			<6198 5533 5094 4958 4935 4930>,
			<6241 5584 5107 4958 4936 4933>,
			<6281 5640 5124 4959 4937 4936>,
			<6316 5699 5145 4962 4938 4935>,
			<6350 5766 5169 4964 4937 4932>,
			<6392 5849 5199 4964 4930 4923>,
			<6445 5952 5241 4969 4932 4925>,
			<6496 6012 5257 4978 4953 4951>,
			<6516 6014 5272 4988 4969 4967>,
			<6563 6061 5300 5003 4977 4970>,
			<6624 6107 5321 5008 4952 4944>,
			<6685 6150 5329 4988 4943 4936>,
			<6763 6194 5343 4988 4945 4938>,
			<6902 6273 5395 4997 4950 4942>,
			<7129 6406 5491 5009 4958 4951>,
			<7928 6612 5626 5039 5005 5002>,
			<7928 6612 5626 5039 5005 5002>,
			<7928 6612 5626 5039 5005 5002>;
	};

};
